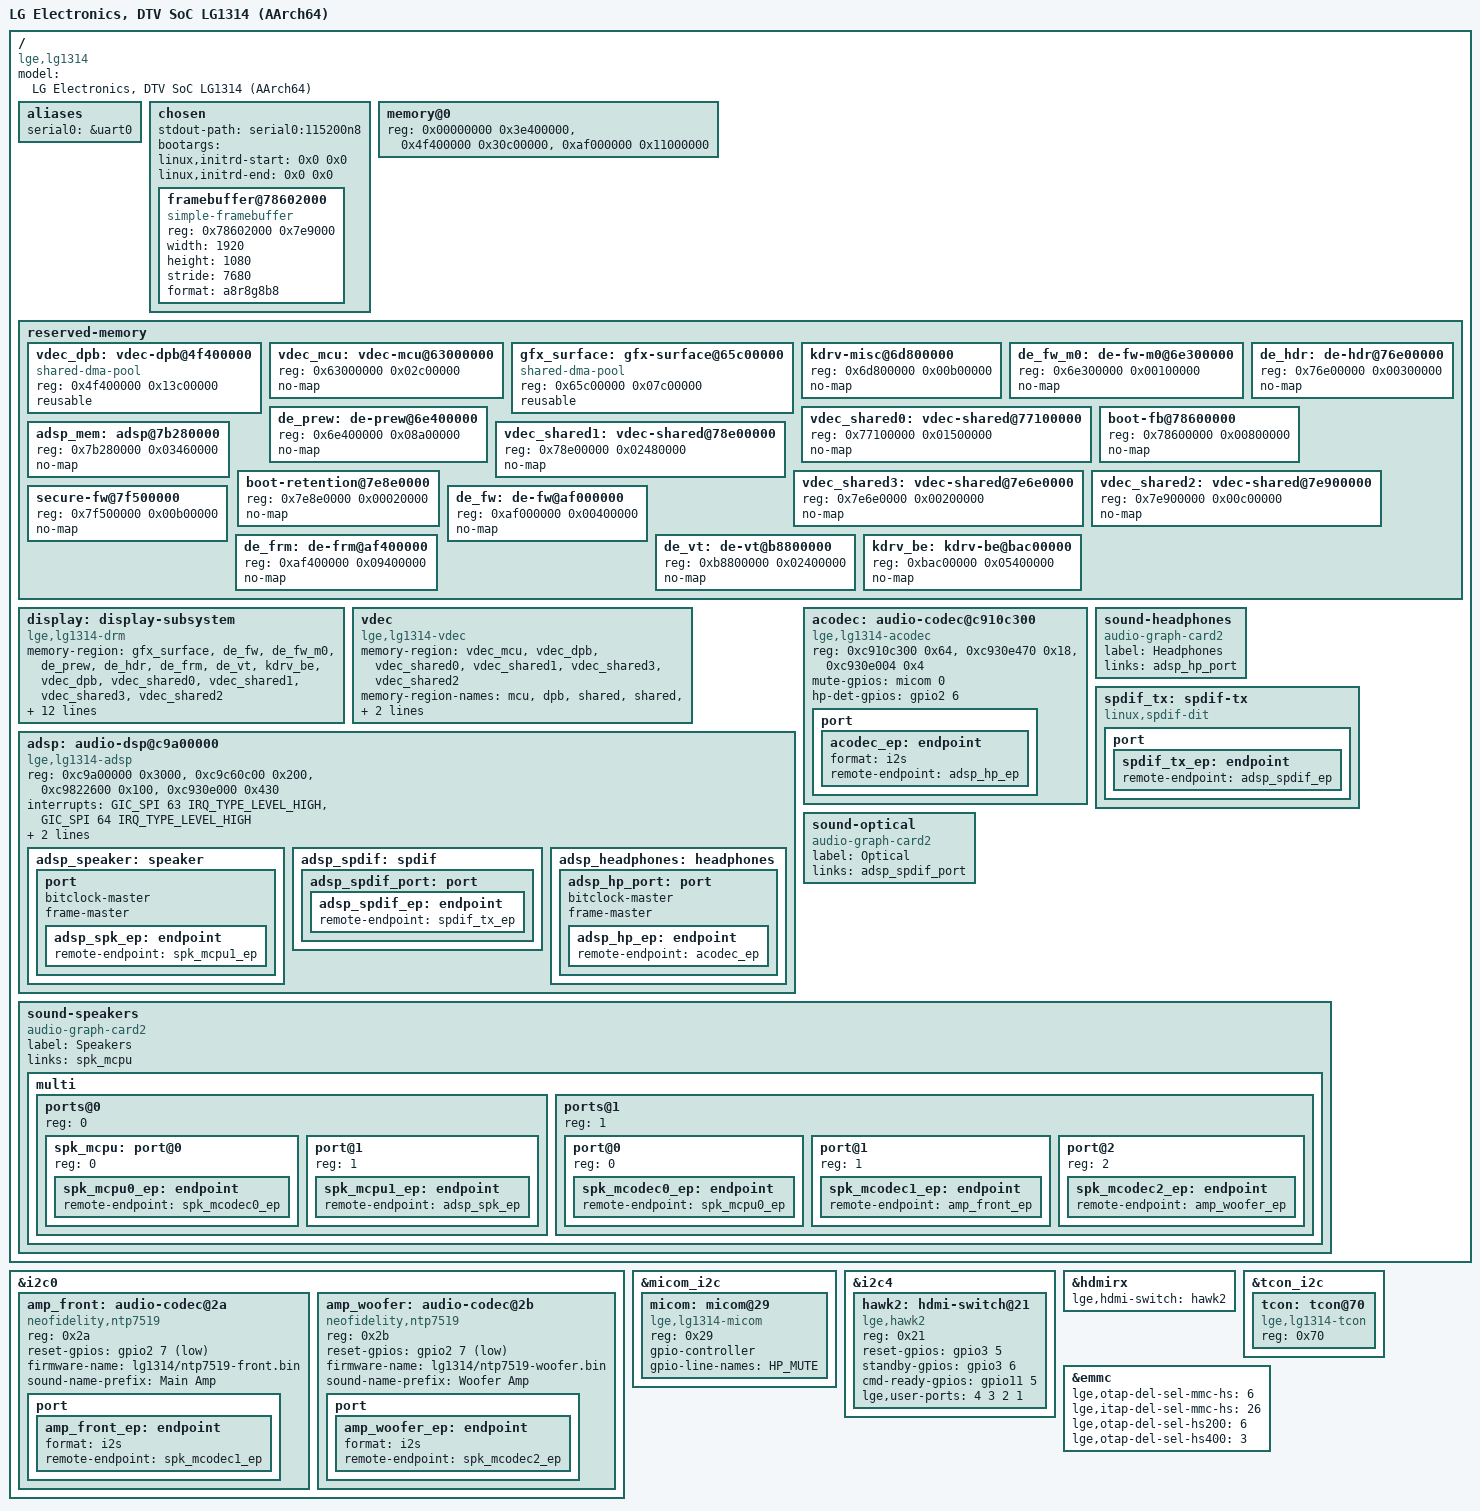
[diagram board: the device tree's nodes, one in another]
// SPDX-License-Identifier: GPL-2.0
/*
 * Derived from a "LJ9 Chassis" board found in an LG OLED55B9PLA TV, booted via lxboot
 */

/dts-v1/;

/memreserve/ 0x0000000000000000 0x0000000000001000;

#include <dt-bindings/gpio/gpio.h>
#include "lg1314.dtsi"

/ {
	model = "LG Electronics, DTV SoC LG1314 (AArch64)";
	compatible = "lge,lg1314", "lge,lg1k";

	aliases {
		serial0 = &uart0;
	};

	chosen {
		stdout-path = "serial0:115200n8";
		/* Reserved, fixed-size slots the boot firmware patches in place (no libfdt).
		 * bootargs: 256 bytes (255 chars + NUL). initrd addrs: 8 bytes each. */
		bootargs = "                                                                                                                                                                                                                                                               ";
		linux,initrd-start = <0x0 0x0>;
		linux,initrd-end = <0x0 0x0>;

		#address-cells = <1>;
		#size-cells = <1>;
		ranges;

		/* OSD0 scanout left live by the boot firmware (linear, 1080p,
		 * upscaled to the panel). Inside kdrv_buffer1, so already no-map. */
		framebuffer@78602000 {
			compatible = "simple-framebuffer";
			reg = <0x78602000 0x7e9000>;
			width = <1920>;
			height = <1080>;
			stride = <7680>;
			format = "a8r8g8b8";
		};
	};

	memory@0 {
		device_type = "memory";
		reg = <0x00000000 0x3e400000>,
		      <0x4f400000 0x30c00000>,
		      <0xaf000000 0x11000000>;
	};

	/*
	 * kdrv_buffer1 (0x4f400000-0x80000000) and kdrv_buffer2
	 * (0xaf000000-0xc0000000) are reserved whole, as by the stock firmware,
	 * and split into the stock platform's regions: the display and decode
	 * firmware are given (or assume) these addresses.
	 */
	reserved-memory {
		#address-cells = <1>;
		#size-cells = <1>;
		ranges;

		/*
		 * Video decoder: decoded pictures. A CMA area (lent to Linux while
		 * unused) so the frames can be shared as dma-bufs. Not below
		 * 0x4f400000: the "gap" 0x3e400000-0x4f3fffff is the same DRAM as
		 * 0xaf000000-0xbfffffff (the display regions below), aliased.
		 */
		vdec_dpb: vdec-dpb@4f400000 {
			compatible = "shared-dma-pool";
			reg = <0x4f400000 0x13c00000>;
			reusable;
		};

		/* Video decoder: stream buffers (24 MiB), then the decode
		 * coprocessor's own pool (IPC area, firmware image, ...). */
		vdec_mcu: vdec-mcu@63000000 {
			reg = <0x63000000 0x02c00000>;
			no-map;
		};

		/*
		 * Graphics surfaces: the scanout pool. CMA rather than a no-map
		 * coherent pool: that one rounds each buffer up to a power of
		 * two, so a 4K AFBC buffer (32 MiB + header) would take 64 MiB.
		 */
		gfx_surface: gfx-surface@65c00000 {
			compatible = "shared-dma-pool";
			reg = <0x65c00000 0x07c00000>;
			reusable;
		};

		kdrv-misc@6d800000 {
			reg = <0x6d800000 0x00b00000>;
			no-map;
		};

		/* Display engine: shared/working memory of its firmware. */
		de_fw_m0: de-fw-m0@6e300000 {
			reg = <0x6e300000 0x00100000>;
			no-map;
		};

		/* Display engine: pre-write + frame-rate-conversion buffers. */
		de_prew: de-prew@6e400000 {
			reg = <0x6e400000 0x08a00000>;
			no-map;
		};

		de_hdr: de-hdr@76e00000 {
			reg = <0x76e00000 0x00300000>;
			no-map;
		};

		/*
		 * Video decoder: overflow for decoded pictures (and the Dolby
		 * Vision enhancement layer's), in four pieces around the boot
		 * scanout, the audio DSPs' memory and the boot ROM's retention
		 * area. The display firmware is given their span as its second
		 * video pool.
		 */
		vdec_shared0: vdec-shared@77100000 {
			reg = <0x77100000 0x01500000>;
			no-map;
		};

		/* The boot firmware's live scanout (framebuffer@78602000). */
		boot-fb@78600000 {
			reg = <0x78600000 0x00800000>;
			no-map;
		};

		vdec_shared1: vdec-shared@78e00000 {
			reg = <0x78e00000 0x02480000>;
			no-map;
		};

		/*
		 * Audio DSPs: stock's layout (MS12 2.0) at stock's address: DSP0
		 * 26 MiB, DSP1 15 MiB (images in their tops), sound engine 2 MiB,
		 * IPC rings 1 MiB, buffer controllers, then the buffer pool.
		 */
		adsp_mem: adsp@7b280000 {
			reg = <0x7b280000 0x03460000>;
			no-map;
		};

		vdec_shared3: vdec-shared@7e6e0000 {
			reg = <0x7e6e0000 0x00200000>;
			no-map;
		};

		/* The boot firmware's key area (stock "sbkey") and the boot
		 * ROM's warm-boot word (0x7e8f0000). */
		boot-retention@7e8e0000 {
			reg = <0x7e8e0000 0x00020000>;
			no-map;
		};

		vdec_shared2: vdec-shared@7e900000 {
			reg = <0x7e900000 0x00c00000>;
			no-map;
		};

		/* Secure firmware (BL31), where the stock one lives. Its first
		 * 2 MiB are firewalled from the non-secure world. */
		secure-fw@7f500000 {
			reg = <0x7f500000 0x00b00000>;
			no-map;
		};

		/* Display engine firmware image. */
		de_fw: de-fw@af000000 {
			reg = <0xaf000000 0x00400000>;
			no-map;
		};

		/* Display engine: frame buffers. */
		de_frm: de-frm@af400000 {
			reg = <0xaf400000 0x09400000>;
			no-map;
		};

		/* Display engine: VTG buffers. */
		de_vt: de-vt@b8800000 {
			reg = <0xb8800000 0x02400000>;
			no-map;
		};

		/* Back end and other blocks' memory. */
		kdrv_be: kdrv-be@bac00000 {
			reg = <0xbac00000 0x05400000>;
			no-map;
		};
	};

	display: display-subsystem {
		compatible = "lge,lg1314-drm";
		memory-region = <&gfx_surface>, <&de_fw>, <&de_fw_m0>, <&de_prew>,
				<&de_hdr>, <&de_frm>, <&de_vt>, <&kdrv_be>,
				<&vdec_dpb>, <&vdec_shared0>, <&vdec_shared1>,
				<&vdec_shared3>, <&vdec_shared2>;
		memory-region-names = "scanout", "de-fw", "de-fw-m0", "de-prew",
				      "de-hdr", "de-frm", "de-vt", "be",
				      "vdec-dpb", "vdec-shared", "vdec-shared",
				      "vdec-shared", "vdec-shared";
		/* Model word for the DE firmware (from the board's hwopt). */
		lge,de-model = <0x00020001>;
		lge,micom = <&micom>;
		lge,tcon = <&tcon>;
		lge,vdec = <&vdec>;
		lge,hdmirx = <&hdmirx>;
		/* OSD mixer vsync, DE sync pulses (video tick), DE IPC */
		interrupts = <GIC_SPI 72 IRQ_TYPE_LEVEL_HIGH>,
			     <GIC_SPI 105 IRQ_TYPE_LEVEL_HIGH>,
			     <GIC_SPI 104 IRQ_TYPE_LEVEL_HIGH>;
	};

	vdec: vdec {
		compatible = "lge,lg1314-vdec";
		memory-region = <&vdec_mcu>, <&vdec_dpb>, <&vdec_shared0>,
				<&vdec_shared1>, <&vdec_shared3>, <&vdec_shared2>;
		memory-region-names = "mcu", "dpb", "shared", "shared", "shared",
				      "shared";
		interrupts = <GIC_SPI 120 IRQ_TYPE_LEVEL_HIGH>;
	};

	adsp: audio-dsp@c9a00000 {
		compatible = "lge,lg1314-adsp";
		/*
		 * audio block, AUD_SYN memory flush, the audio bus port's
		 * protector, audio clocks (BMC_SYN + CTOP_BMC)
		 */
		reg = <0xc9a00000 0x3000>,
		      <0xc9c60c00 0x200>,
		      <0xc9822600 0x100>,
		      <0xc930e000 0x430>;
		reg-names = "aud", "syn", "mpro", "bmc";
		/* DSP0 -> host, DSP1 -> host */
		interrupts = <GIC_SPI 63 IRQ_TYPE_LEVEL_HIGH>,
			     <GIC_SPI 64 IRQ_TYPE_LEVEL_HIGH>;
		memory-region = <&adsp_mem>;
		/* HDMI input audio follows the input shown */
		lge,hdmirx = <&hdmirx>;

		/* DSP1's outputs: one DAI each */
		adsp_speaker: speaker {
			#sound-dai-cells = <0>;

			/* I2S to the amplifiers; the SoC drives the clocks */
			port {
				bitclock-master;
				frame-master;
				adsp_spk_ep: endpoint {
					remote-endpoint = <&spk_mcpu1_ep>;
				};
			};
		};

		adsp_spdif: spdif {
			#sound-dai-cells = <0>;

			adsp_spdif_port: port {
				adsp_spdif_ep: endpoint {
					remote-endpoint = <&spdif_tx_ep>;
				};
			};
		};

		/* "sub" I2S to the internal DAC */
		adsp_headphones: headphones {
			#sound-dai-cells = <0>;

			adsp_hp_port: port {
				bitclock-master;
				frame-master;
				adsp_hp_ep: endpoint {
					remote-endpoint = <&acodec_ep>;
				};
			};
		};
	};

	/* Internal DAC: headphone / line out. */
	acodec: audio-codec@c910c300 {
		compatible = "lge,lg1314-acodec";
		/* MIP_DIG DAC, CTOP_BMC analogue, BMC_SYN audio reset (shared) */
		reg = <0xc910c300 0x64>,
		      <0xc930e470 0x18>,
		      <0xc930e004 0x4>;
		reg-names = "dac", "atop", "reset";
		#sound-dai-cells = <0>;
		/* after the DAC: the MICOM's headphone mute; stock GPIO 22 = plugged */
		mute-gpios = <&micom 0 GPIO_ACTIVE_HIGH>;
		hp-det-gpios = <&gpio2 6 GPIO_ACTIVE_HIGH>;

		port {
			acodec_ep: endpoint {
				format = "i2s";
				remote-endpoint = <&adsp_hp_ep>;
			};
		};
	};

	sound-headphones {
		compatible = "audio-graph-card2";
		label = "Headphones";
		links = <&adsp_hp_port>;
	};

	spdif_tx: spdif-tx {
		compatible = "linux,spdif-dit";
		#sound-dai-cells = <0>;

		port {
			spdif_tx_ep: endpoint {
				remote-endpoint = <&adsp_spdif_ep>;
			};
		};
	};

	sound-optical {
		compatible = "audio-graph-card2";
		label = "Optical";
		links = <&adsp_spdif_port>;
	};

	/* Speakers: one stereo stream into both amplifiers. */
	sound-speakers {
		compatible = "audio-graph-card2";
		label = "Speakers";
		links = <&spk_mcpu>;

		multi {
			#address-cells = <1>;
			#size-cells = <0>;

			ports@0 {
				reg = <0>;
				#address-cells = <1>;
				#size-cells = <0>;

				spk_mcpu: port@0 {
					reg = <0>;
					spk_mcpu0_ep: endpoint {
						remote-endpoint = <&spk_mcodec0_ep>;
					};
				};
				port@1 {
					reg = <1>;
					spk_mcpu1_ep: endpoint {
						remote-endpoint = <&adsp_spk_ep>;
					};
				};
			};

			ports@1 {
				reg = <1>;
				#address-cells = <1>;
				#size-cells = <0>;

				port@0 {
					reg = <0>;
					spk_mcodec0_ep: endpoint {
						remote-endpoint = <&spk_mcpu0_ep>;
					};
				};
				port@1 {
					reg = <1>;
					spk_mcodec1_ep: endpoint {
						remote-endpoint = <&amp_front_ep>;
					};
				};
				port@2 {
					reg = <2>;
					spk_mcodec2_ep: endpoint {
						remote-endpoint = <&amp_woofer_ep>;
					};
				};
			};
		};
	};
};

/*
 * Speaker amplifiers: both take the same I2S stereo pair (DSP1's speaker
 * output) and split the bands with their own EQ. One reset line for both
 * (stock GPIO 23).
 */
&i2c0 {
	amp_front: audio-codec@2a {
		compatible = "neofidelity,ntp7519";
		reg = <0x2a>;
		#sound-dai-cells = <0>;
		reset-gpios = <&gpio2 7 GPIO_ACTIVE_LOW>;
		firmware-name = "lg1314/ntp7519-front.bin";
		sound-name-prefix = "Main Amp";

		port {
			amp_front_ep: endpoint {
				format = "i2s";
				remote-endpoint = <&spk_mcodec1_ep>;
			};
		};
	};

	amp_woofer: audio-codec@2b {
		compatible = "neofidelity,ntp7519";
		reg = <0x2b>;
		#sound-dai-cells = <0>;
		reset-gpios = <&gpio2 7 GPIO_ACTIVE_LOW>;
		firmware-name = "lg1314/ntp7519-woofer.bin";
		sound-name-prefix = "Woofer Amp";

		port {
			amp_woofer_ep: endpoint {
				format = "i2s";
				remote-endpoint = <&spk_mcodec2_ep>;
			};
		};
	};
};

&micom_i2c {
	micom: micom@29 {
		compatible = "lge,lg1314-micom";
		reg = <0x29>;
		/* output ports (gpio-lg1314-micom) */
		gpio-controller;
		#gpio-cells = <2>;
		gpio-line-names = "HP_MUTE";
	};
};

/*
 * HDMI 2.1 switch in front of the SoC's HDMI receivers (stock "HAWK2", GPIOs 29/30
 * reset/standby, 93 CMD_READY). Its port n feeds SoC port n; connector HDMI k is
 * on switch port 4 - k.
 */
&i2c4 {
	hawk2: hdmi-switch@21 {
		compatible = "lge,hawk2";
		reg = <0x21>;
		reset-gpios = <&gpio3 5 GPIO_ACTIVE_HIGH>;
		standby-gpios = <&gpio3 6 GPIO_ACTIVE_HIGH>;
		cmd-ready-gpios = <&gpio11 5 GPIO_ACTIVE_HIGH>;
		lge,user-ports = <4 3 2 1>;
	};
};

&hdmirx {
	lge,hdmi-switch = <&hawk2>;
};

/* The OLED panel's timing controller (16-bit register addresses). */
&tcon_i2c {
	tcon: tcon@70 {
		compatible = "lge,lg1314-tcon";
		reg = <0x70>;
	};
};

&emmc {
	lge,otap-del-sel-mmc-hs = <6>;
	lge,itap-del-sel-mmc-hs = <26>;
	lge,otap-del-sel-hs200 = <6>;
	lge,otap-del-sel-hs400 = <3>;
};
